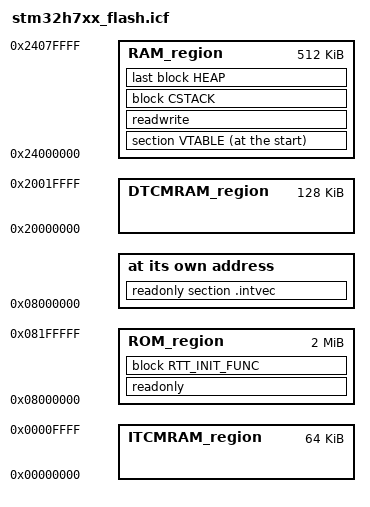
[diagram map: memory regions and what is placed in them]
/*###ICF### Section handled by ICF editor, don't touch! ****/
/*-Editor annotation file-*/
/* IcfEditorFile="$TOOLKIT_DIR$\config\ide\IcfEditor\cortex_v1_0.xml" */
/*-Specials-*/
define symbol __ICFEDIT_intvec_start__ = 0x08000000;
/*-Memory Regions-*/
define symbol __ICFEDIT_region_ROM_start__     = 0x08000000;
define symbol __ICFEDIT_region_ROM_end__       = 0x081FFFFF;
define symbol __ICFEDIT_region_RAM_start__     = 0x24000000;
define symbol __ICFEDIT_region_RAM_end__       = 0x2407FFFF;
define symbol __ICFEDIT_region_ITCMRAM_start__ = 0x00000000;
define symbol __ICFEDIT_region_ITCMRAM_end__   = 0x0000FFFF;
define symbol __ICFEDIT_region_DTCMRAM_start__ = 0x20000000;
define symbol __ICFEDIT_region_DTCMRAM_end__   = 0x2001FFFF;
/*Export the end address of ram, to avoid hard-code heap size in application*/
export symbol __ICFEDIT_region_RAM_end__;
/*-Sizes-*/
define symbol __ICFEDIT_size_cstack__ = 0x800;
define symbol __ICFEDIT_size_heap__   = 0x000;
/**** End of ICF editor section. ###ICF###*/


define memory mem with size = 4G;
define region ROM_region   = mem:[from __ICFEDIT_region_ROM_start__   to __ICFEDIT_region_ROM_end__];
define region RAM_region   = mem:[from __ICFEDIT_region_RAM_start__   to __ICFEDIT_region_RAM_end__];
define region ITCMRAM_region   = mem:[from __ICFEDIT_region_ITCMRAM_start__   to __ICFEDIT_region_ITCMRAM_end__];
define region DTCMRAM_region   = mem:[from __ICFEDIT_region_DTCMRAM_start__   to __ICFEDIT_region_DTCMRAM_end__];

define block CSTACK    with alignment = 8, size = __ICFEDIT_size_cstack__   { };
define block HEAP      with alignment = 8, size = __ICFEDIT_size_heap__     { };
define block RTT_INIT_FUNC with fixed order { readonly section .rti_fn* };

initialize by copy { readwrite };
//initialize by copy with packing = none { section __DLIB_PERTHREAD }; // Required in a multi-threaded application
do not initialize  { section .noinit };

keep { section FSymTab };
keep { section VSymTab };
keep { section .rti_fn* };
place at address mem:__ICFEDIT_intvec_start__ { readonly section .intvec };
// Place the RAM vector table at the start of SRAM.
place at start of RAM_region { section VTABLE };
//place at start of DTCMRAM_region { block CSTACK};

place in ROM_region   { readonly, block RTT_INIT_FUNC  };
place in RAM_region   { readwrite, block CSTACK,  last block HEAP };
